AUTOSAR XML (schema 4-2-1)
package /StartApplication/StartApplication_swc/ComponentTypes
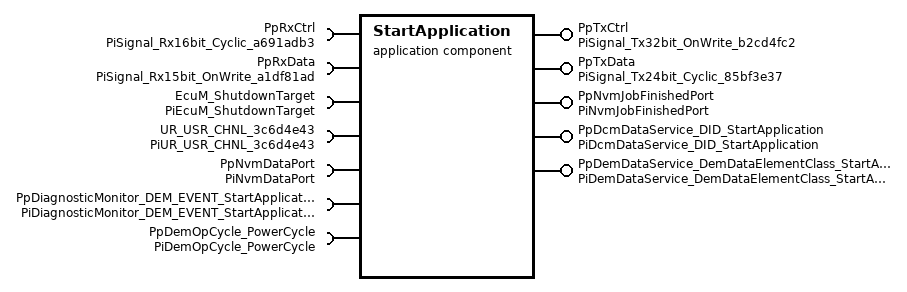
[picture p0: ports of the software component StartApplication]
  application sw component type StartApplication
    provide port PpTxCtrl: nonqueued-sender-com-spec{data-element=DeSignal_Tx32bit_OnWrite_b2cd4fc2, init-value=31}, provided-interface=PiSignal_Tx32bit_OnWrite_b2cd4fc2
    provide port PpTxData: nonqueued-sender-com-spec{data-element=DeSignal_Tx24bit_Cyclic_85bf3e37, init-value=0}, provided-interface=PiSignal_Tx24bit_Cyclic_85bf3e37
    4 x require port:
      PpRxCtrl: nonqueued-receiver-com-spec{data-element=DeSignal_Rx16bit_Cyclic_a691adb3, handle-out-of-range-status=SILENT, init-value=32768}, required-interface=PiSignal_Rx16bit_Cyclic_a691adb3
      PpRxData: nonqueued-receiver-com-spec{data-element=DeSignal_Rx15bit_OnWrite_a1df81ad, handle-out-of-range-status=SILENT, init-value=25}, required-interface=PiSignal_Rx15bit_OnWrite_a1df81ad
      EcuM_ShutdownTarget: required-interface=PiEcuM_ShutdownTarget
      UR_USR_CHNL_3c6d4e43: required-interface=PiUR_USR_CHNL_3c6d4e43
    provide port PpNvmJobFinishedPort: provided-interface=PiNvmJobFinishedPort
    require port PpNvmDataPort: required-interface=PiNvmDataPort
    require port PpDiagnosticMonitor_DEM_EVENT_StartApplication: required-interface=PiDiagnosticMonitor_DEM_EVENT_StartApplication
    require port PpDemOpCycle_PowerCycle: required-interface=PiDemOpCycle_PowerCycle
    provide port PpDcmDataService_DID_StartApplication: provided-interface=PiDcmDataService_DID_StartApplication
    provide port PpDemDataService_DemDataElementClass_StartApplication: provided-interface=PiDemDataService_DemDataElementClass_StartApplication
    behavior StartApplicationInternalBehavior: handle-termination-and-restart=NO-SUPPORT
      ar-typed-per-instance-memorys:
        16 x data:
          TxCtrlSigValue: type=uint32
          TxDataSigValue: type=uint32
          Uptime: type=uint8
          COM_RxSigValue0: type=uint16
          COM_TxSigValue0: type=uint32
          MEM_DataBuffer: type=uint8
          MEM_BlockState: type=EnumMEM_BlockStateType
          DIAG_LastRxData: type=uint8
          NM_ApplState: type=EnumNM_ApplStateType
          NM_ActiveChannelHasFullComRequest: type=uint8
          NM_BusSleepModeTimer: type=uint8
          NM_ActiveComMChannel: type=uint8
          NM_ActiveComMUsers: type=uint32
          XcpPimUpload: sw-calibration-access=READ-WRITE, type=uint16
          XcpPimDownload: sw-calibration-access=READ-WRITE, type=uint16
          ActiveComponent: type=EnumActiveComponentType
      4 x timing event:
        Timer_StartApplication_Cyclic1ms: start-on-event=StartApplication_Cyclic1ms, period=0.001
        Timer_StartApplication_Cyclic10ms: start-on-event=StartApplication_Cyclic10ms, period=0.01
        Timer_StartApplication_Cyclic250ms: start-on-event=StartApplication_Cyclic250ms, period=0.25
        Timer_StartApplication_Cyclic1000ms: start-on-event=StartApplication_Cyclic1000ms, period=1
      init event Timer_StartApplication_Init: start-on-event=StartApplication_Init
      operation invoked event OpEventStartApplication_MEM_JobFinished_JobFinished_PpNvmJobFinishedPort: start-on-event=StartApplication_MEM_JobFinished, operation=PpNvmJobFinishedPort.JobFinished
      data received event DataReceivedEvent_StartApplication_OnDataRec_RxCtrl_PpRxCtrl_DeSignal_Rx16bit_Cyclic_a691adb3: start-on-event=StartApplication_OnDataRec_RxCtrl, data=PpRxCtrl.DeSignal_Rx16bit_Cyclic_a691adb3
      data received event DataReceivedEvent_StartApplication_OnDataRec_RxData_PpRxData_DeSignal_Rx15bit_OnWrite_a1df81ad: start-on-event=StartApplication_OnDataRec_RxData, data=PpRxData.DeSignal_Rx15bit_OnWrite_a1df81ad
      4 x operation invoked event:
        OpEventStartApplication_DIAG_DcmReadData_ReadData_PpDcmDataService_DID_StartApplication: start-on-event=StartApplication_DIAG_DcmReadData, operation=PpDcmDataService_DID_StartApplication.ReadData
        OpEventStartApplication_DIAG_DcmWriteData_WriteData_PpDcmDataService_DID_StartApplication: start-on-event=StartApplication_DIAG_DcmWriteData, operation=PpDcmDataService_DID_StartApplication.WriteData
        OpEventStartApplication_DIAG_ConditionCheckRead_ConditionCheckRead_PpDcmDataService_DID_StartApplication: start-on-event=StartApplication_DIAG_ConditionCheckRead, operation=PpDcmDataService_DID_StartApplication.ConditionCheckRead
        OpEventStartApplication_DIAG_DemReadData_ReadData_PpDemDataService_DemDataElementClass_StartApplication: start-on-event=StartApplication_DIAG_DemReadData, operation=PpDemDataService_DemDataElementClass_StartApplication.ReadData
      explicit-inter-runnable-variables:
        data IrvOccuranceCounterDid: type=uint16, init-value=0
      port-api-options:
        enable-take-address=true, indirect-api=false, port=PpTxCtrl
        enable-take-address=true, indirect-api=false, port=PpTxData
        enable-take-address=true, indirect-api=false, port=PpRxCtrl
        enable-take-address=true, indirect-api=false, port=PpRxData
        enable-take-address=true, indirect-api=false, port=EcuM_ShutdownTarget
        enable-take-address=true, indirect-api=false, port=UR_USR_CHNL_3c6d4e43
        enable-take-address=true, indirect-api=false, port=PpNvmJobFinishedPort
        enable-take-address=true, indirect-api=false, port=PpNvmDataPort
        enable-take-address=true, indirect-api=false, port=PpDiagnosticMonitor_DEM_EVENT_StartApplication
        enable-take-address=true, indirect-api=false, port=PpDemOpCycle_PowerCycle
        enable-take-address=true, indirect-api=false, port=PpDcmDataService_DID_StartApplication
        enable-take-address=true, indirect-api=false, port=PpDemDataService_DemDataElementClass_StartApplication
      12 x runnable:
        StartApplication_Cyclic1ms
        StartApplication_Cyclic10ms
        StartApplication_Cyclic250ms
          data-receive-point-by-arguments:
            access DataReceivePointStartApplication_Cyclic250ms_PpRxData_DeSignal_Rx15bit_OnWrite_a1df81ad: accessed-variable=PpRxData.DeSignal_Rx15bit_OnWrite_a1df81ad
          data-send-points:
            access DataSendPointStartApplication_Cyclic250ms_PpTxCtrl_DeSignal_Tx32bit_OnWrite_b2cd4fc2: accessed-variable=PpTxCtrl.DeSignal_Tx32bit_OnWrite_b2cd4fc2
            access DataSendPointStartApplication_Cyclic250ms_PpTxData_DeSignal_Tx24bit_Cyclic_85bf3e37: accessed-variable=PpTxData.DeSignal_Tx24bit_Cyclic_85bf3e37
          read-local-variables:
            access StartApplication_Cyclic250ms_IrvOccuranceCounterDid_DIRECT_READ: accessed-variable=IrvOccuranceCounterDid
          sync call OpServerCallStartApplication_Cyclic250ms_GetCurrentComMode_UR_USR_CHNL_3c6d4e43: operation=UR_USR_CHNL_3c6d4e43.GetCurrentComMode, timeout=0
          sync call OpServerCallStartApplication_Cyclic250ms_RequestComMode_UR_USR_CHNL_3c6d4e43: operation=UR_USR_CHNL_3c6d4e43.RequestComMode, timeout=0
          sync call OpServerCallStartApplication_Cyclic250ms_ReadBlock_PpNvmDataPort: operation=PpNvmDataPort.ReadBlock, timeout=0
        StartApplication_Cyclic1000ms
        StartApplication_Init: can-be-invoked-concurrently=true
          sync call OpServerCallStartApplication_Init_RequestComMode_UR_USR_CHNL_3c6d4e43: operation=UR_USR_CHNL_3c6d4e43.RequestComMode, timeout=0
        StartApplication_MEM_JobFinished: can-be-invoked-concurrently=true
          data-send-points:
            access DataSendPointStartApplication_MEM_JobFinished_PpTxCtrl_DeSignal_Tx32bit_OnWrite_b2cd4fc2: accessed-variable=PpTxCtrl.DeSignal_Tx32bit_OnWrite_b2cd4fc2
        StartApplication_OnDataRec_RxCtrl
          data-receive-point-by-arguments:
            access DataReceivePointStartApplication_OnDataRec_RxCtrl_PpRxCtrl_DeSignal_Rx16bit_Cyclic_a691adb3: accessed-variable=PpRxCtrl.DeSignal_Rx16bit_Cyclic_a691adb3
          data-send-points:
            access DataSendPointStartApplication_OnDataRec_RxCtrl_PpTxCtrl_DeSignal_Tx32bit_OnWrite_b2cd4fc2: accessed-variable=PpTxCtrl.DeSignal_Tx32bit_OnWrite_b2cd4fc2
          sync call OpServerCallStartApplication_OnDataRec_RxCtrl_SetOperationCycleState_PpDemOpCycle_PowerCycle: operation=PpDemOpCycle_PowerCycle.SetOperationCycleState, timeout=0
        StartApplication_OnDataRec_RxData
          data-receive-point-by-arguments:
            access DataReceivePointStartApplication_OnDataRec_RxData_PpRxData_DeSignal_Rx15bit_OnWrite_a1df81ad: accessed-variable=PpRxData.DeSignal_Rx15bit_OnWrite_a1df81ad
          data-send-points:
            access DataSendPointStartApplication_OnDataRec_RxData_PpTxCtrl_DeSignal_Tx32bit_OnWrite_b2cd4fc2: accessed-variable=PpTxCtrl.DeSignal_Tx32bit_OnWrite_b2cd4fc2
          read-local-variables:
            access StartApplication_OnDataRec_RxData_IrvOccuranceCounterDid_DIRECT_READ: accessed-variable=IrvOccuranceCounterDid
          sync call OpServerCallStartApplication_OnDataRec_RxData_SelectShutdownTarget_EcuM_ShutdownTarget: operation=EcuM_ShutdownTarget.SelectShutdownTarget, timeout=0
          sync call OpServerCallStartApplication_OnDataRec_RxData_WriteBlock_PpNvmDataPort: operation=PpNvmDataPort.WriteBlock, timeout=0
          sync call OpServerCallStartApplication_OnDataRec_RxData_SetEventStatus_PpDiagnosticMonitor_DEM_EVENT_StartApplication: operation=PpDiagnosticMonitor_DEM_EVENT_StartApplication.SetEventStatus, timeout=0
          written-local-variables:
            access StartApplication_OnDataRec_RxData_IrvOccuranceCounterDid_DIRECT_WRITE: accessed-variable=IrvOccuranceCounterDid
        StartApplication_DIAG_DcmReadData: can-be-invoked-concurrently=true
          read-local-variables:
            access StartApplication_DIAG_DcmReadData_IrvOccuranceCounterDid_DIRECT_READ: accessed-variable=IrvOccuranceCounterDid
        StartApplication_DIAG_DcmWriteData: can-be-invoked-concurrently=true
          written-local-variables:
            access StartApplication_DIAG_DcmWriteData_IrvOccuranceCounterDid_DIRECT_WRITE: accessed-variable=IrvOccuranceCounterDid
        StartApplication_DIAG_ConditionCheckRead: can-be-invoked-concurrently=true
        StartApplication_DIAG_DemReadData: can-be-invoked-concurrently=true
          read-local-variables:
            access StartApplication_DIAG_DemReadData_IrvOccuranceCounterDid_DIRECT_READ: accessed-variable=IrvOccuranceCounterDid
  swc implementation StartApplicationImplementation: programming-language=C, behavior=StartApplicationInternalBehavior
package /StartApplication/StartApplication_swc/DataTypes
  14 x impl type:
    EnumMEM_BlockStateType: compu {0=MEM_STATE_UNKNOWN, 1=MEM_STATE_WRITE_PENDING, 2=MEM_STATE_WRITE_FINISHED, 3=MEM_STATE_READ_PENDING, 4=MEM_STATE_READ_FINISHED, 5=MEM_STATE_WRITE_FAILED, 6=MEM_STATE_READ_FAILED}, implementation-data-type=uint8
    EnumNM_ApplStateType: compu {0=NM_APPL_STATE_FULL_COMM_EXTERN, 1=NM_APPL_STATE_FULL_COMM_INTERN, 2=NM_APPL_STATE_NO_COMM_EXTERN}, implementation-data-type=uint8
    EcuM_StateType: compu {15=ECUM_SUBSTATE_MASK, 16=ECUM_STATE_STARTUP, 17=ECUM_STATE_STARTUP_ONE, 18=ECUM_STATE_STARTUP_TWO, 32=ECUM_STATE_WAKEUP, 33=ECUM_STATE_WAKEUP_ONE, 34=ECUM_STATE_WAKEUP_VALIDATION, 35=ECUM_STATE_WAKEUP_REACTION, 36=ECUM_STATE_WAKEUP_TWO, 37=ECUM_STATE_WAKEUP_WAKESLEEP, 38=ECUM_STATE_WAKEUP_TTII, 48=ECUM_STATE_RUN, 50=ECUM_STATE_APP_RUN, 51=ECUM_STATE_APP_POST_RUN, 64=ECUM_STATE_SHUTDOWN, 68=ECUM_STATE_PREP_SHUTDOWN, 73=ECUM_STATE_GO_SLEEP, 77=ECUM_STATE_GO_OFF_ONE, 78=ECUM_STATE_GO_OFF_TWO, 80=ECUM_STATE_SLEEP, 128=ECUM_STATE_OFF, 144=ECUM_STATE_RESET}, implementation-data-type=uint8
    EcuM_SleepModeType: implementation-data-type=uint8
    EcuM_ShutdownCauseType: compu {0=ECUM_CAUSE_UNKNOWN, 1=ECUM_CAUSE_ECU_STATE, 2=ECUM_CAUSE_WDGM, 3=ECUM_CAUSE_DCM}, implementation-data-type=uint8
    ComM_ModeType: compu {0=COMM_NO_COMMUNICATION, 1=COMM_SILENT_COMMUNICATION, 2=COMM_FULL_COMMUNICATION}, implementation-data-type=uint8
    NvM_ServiceIdType: compu {6=NVM_READ_BLOCK, 7=NVM_WRITE_BLOCK, 8=NVM_RESTORE_BLOCK_DEFAULTS, 9=NVM_ERASE_BLOCK, 11=NVM_INVALIDATE_NV_BLOCK, 12=NVM_READ_ALL}, implementation-data-type=uint8
    NvM_RequestResultType: compu {0=NVM_REQ_OK, 1=NVM_REQ_NOT_OK, 2=NVM_REQ_PENDING, 3=NVM_REQ_INTEGRITY_FAILED, 4=NVM_REQ_BLOCK_SKIPPED, 5=NVM_REQ_NV_INVALIDATED, 6=NVM_REQ_CANCELED, 7=NVM_REQ_REDUNDANCY_FAILED, 8=NVM_REQ_RESTORED_FROM_ROM}, implementation-data-type=uint8
    Dem_EventStatusType: compu {0=DEM_EVENT_STATUS_PASSED, 1=DEM_EVENT_STATUS_FAILED, 2=DEM_EVENT_STATUS_PREPASSED, 3=DEM_EVENT_STATUS_PREFAILED, 4=DEM_EVENT_STATUS_FDC_THRESHOLD_REACHED}, implementation-data-type=uint8
    Dem_OperationCycleStateType: compu {0=DEM_CYCLE_STATE_START, 1=DEM_CYCLE_STATE_END}, implementation-data-type=uint8
    Dcm_Data2ByteType: category=ARRAY, sw-calibration-access=READ-ONLY
      element Dcm_Data2ByteTypeElement: array-size=2, array-size-semantics=FIXED-SIZE, implementation-data-type=uint8
    Dcm_NegativeResponseCodeType: compu {0=DCM_E_POSITIVERESPONSE, 16=DCM_E_GENERALREJECT, 17=DCM_E_SERVICENOTSUPPORTED, 18=DCM_E_SUBFUNCTIONNOTSUPPORTED, 19=DCM_E_INCORRECTMESSAGELENGTHORINVALIDFORMAT, 20=DCM_E_RESPONSETOOLONG, 33=DCM_E_BUSYREPEATREQUEST, 34=DCM_E_CONDITIONSNOTCORRECT, 36=DCM_E_REQUESTSEQUENCEERROR, 37=DCM_E_NORESPONSEFROMSUBNETCOMPONENT, 38=DCM_E_FAILUREPREVENTSEXECUTIONOFREQUESTEDACTION, 49=DCM_E_REQUESTOUTOFRANGE, 51=DCM_E_SECURITYACCESSDENIED, 53=DCM_E_INVALIDKEY, 54=DCM_E_EXCEEDNUMBEROFATTEMPTS, 55=DCM_E_REQUIREDTIMEDELAYNOTEXPIRED, 112=DCM_E_UPLOADDOWNLOADNOTACCEPTED, 113=DCM_E_TRANSFERDATASUSPENDED, 114=DCM_E_GENERALPROGRAMMINGFAILURE, 115=DCM_E_WRONGBLOCKSEQUENCECOUNTER, 120=DCM_E_REQUESTCORRECTLYRECEIVEDRESPONSEPENDING, 126=DCM_E_SUBFUNCTIONNOTSUPPORTEDINACTIVESESSION, 127=DCM_E_SERVICENOTSUPPORTEDINACTIVESESSION, 129=DCM_E_RPMTOOHIGH, 130=DCM_E_RPMTOOLOW, 131=DCM_E_ENGINEISRUNNING, 132=DCM_E_ENGINEISNOTRUNNING, 133=DCM_E_ENGINERUNTIMETOOLOW, 134=DCM_E_TEMPERATURETOOHIGH, 135=DCM_E_TEMPERATURETOOLOW, 136=DCM_E_VEHICLESPEEDTOOHIGH, 137=DCM_E_VEHICLESPEEDTOOLOW, 138=DCM_E_THROTTLE_PEDALTOOHIGH, 139=DCM_E_THROTTLE_PEDALTOOLOW, 140=DCM_E_TRANSMISSIONRANGENOTINNEUTRAL, 141=DCM_E_TRANSMISSIONRANGENOTINGEAR, 143=DCM_E_BRAKESWITCH_NOTCLOSED, 144=DCM_E_SHIFTERLEVERNOTINPARK, 145=DCM_E_TORQUECONVERTERCLUTCHLOCKED, 146=DCM_E_VOLTAGETOOHIGH, 147=DCM_E_VOLTAGETOOLOW}, implementation-data-type=uint8
    DataArray_Type_2: category=ARRAY, sw-calibration-access=READ-ONLY
      element DataArray_Type_2Element: array-size=2, array-size-semantics=FIXED-SIZE, implementation-data-type=uint8
    EnumActiveComponentType: compu {0=STARTAPPLICATION_ACTIVE_COMPONENT_COM_RXTX, 1=STARTAPPLICATION_ACTIVE_COMPONENT_MEM, 2=STARTAPPLICATION_ACTIVE_COMPONENT_DIAG, 3=STARTAPPLICATION_ACTIVE_COMPONENT_COM_TXONLY, 5=STARTAPPLICATION_ACTIVE_COMPONENT_XCP, 10=STARTAPPLICATION_ACTIVE_COMPONENT_NM, 255=STARTAPPLICATION_ACTIVE_COMPONENT_INVALID}, implementation-data-type=uint8
package /StartApplication/StartApplication_swc/Interfaces
  4 x sender receiver interface:
    PiSignal_Tx32bit_OnWrite_b2cd4fc2
      data DeSignal_Tx32bit_OnWrite_b2cd4fc2: type=uint32
    PiSignal_Tx24bit_Cyclic_85bf3e37
      data DeSignal_Tx24bit_Cyclic_85bf3e37: type=uint32
    PiSignal_Rx16bit_Cyclic_a691adb3
      data DeSignal_Rx16bit_Cyclic_a691adb3: type=uint16
    PiSignal_Rx15bit_OnWrite_a1df81ad
      data DeSignal_Rx15bit_OnWrite_a1df81ad: type=uint16
  8 x client server interface, all with is-service=true, service-kind=VENDOR-SPECIFIC:
    PiEcuM_ShutdownTarget
      5 x operation, all with possible-error=PiEcuM_ShutdownTarget/E_NOT_OK:
        SelectShutdownTarget
          arg targetState: type=EcuM_StateType, direction=IN
          arg resetSleepMode: type=EcuM_SleepModeType, direction=IN
        GetShutdownTarget
          arg target: type=EcuM_StateType, direction=OUT
          arg resetSleepMode: type=EcuM_SleepModeType, direction=OUT
        GetLastShutdownTarget
          arg target: type=EcuM_StateType, direction=OUT
          arg resetSleepMode: type=EcuM_SleepModeType, direction=OUT
        SelectShutdownCause
          arg shutdownCause: type=EcuM_ShutdownCauseType, direction=IN
        GetShutdownCause
          arg shutdownCause: type=EcuM_ShutdownCauseType, direction=OUT
      error E_NOT_OK: error-code=1
    PiUR_USR_CHNL_3c6d4e43
      4 x operation:
        GetCurrentComMode: possible-error=PiUR_USR_CHNL_3c6d4e43/E_NOT_OK
          arg ComMode: type=ComM_ModeType, direction=OUT
        GetMaxComMode: possible-error=PiUR_USR_CHNL_3c6d4e43/E_NOT_OK
          arg ComMode: type=ComM_ModeType, direction=OUT
        GetRequestedComMode: possible-error=PiUR_USR_CHNL_3c6d4e43/E_NOT_OK
          arg ComMode: type=ComM_ModeType, direction=OUT
        RequestComMode: possible-error=[PiUR_USR_CHNL_3c6d4e43/E_NOT_OK, E_MODE_LIMITATION]
          arg ComMode: type=ComM_ModeType, direction=IN
      error E_NOT_OK: error-code=1
      error E_MODE_LIMITATION: error-code=2
    PiNvmDataPort
      operation WriteBlock: possible-error=PiNvmDataPort/E_NOT_OK
        arg SrcPtr: type=dtRef_const_VOID, direction=IN
      operation ReadBlock: possible-error=PiNvmDataPort/E_NOT_OK
        arg DstPtr: type=dtRef_VOID, direction=IN
      error E_NOT_OK: error-code=1
    PiNvmJobFinishedPort
      operation JobFinished
        arg ServiceId: type=NvM_ServiceIdType, direction=IN
        arg JobResult: type=NvM_RequestResultType, direction=IN
    PiDiagnosticMonitor_DEM_EVENT_StartApplication
      operation SetEventStatus: possible-error=PiDiagnosticMonitor_DEM_EVENT_StartApplication/E_NOT_OK
        arg EventStatus: type=Dem_EventStatusType, direction=IN
      operation ResetEventStatus: possible-error=PiDiagnosticMonitor_DEM_EVENT_StartApplication/E_NOT_OK
      error E_NOT_OK: error-code=1
    PiDemOpCycle_PowerCycle
      operation SetOperationCycleState: possible-error=PiDemOpCycle_PowerCycle/E_NOT_OK
        arg CycleState: type=Dem_OperationCycleStateType, direction=IN
      error E_NOT_OK: error-code=1
    PiDcmDataService_DID_StartApplication
      operation WriteData
        arg Data: type=Dcm_Data2ByteType, direction=IN
        arg ErrorCode: type=Dcm_NegativeResponseCodeType, direction=OUT
      operation ReadData
        arg Data: type=Dcm_Data2ByteType, direction=OUT
      operation ConditionCheckRead
        arg ErrorCode: type=Dcm_NegativeResponseCodeType, direction=OUT
    PiDemDataService_DemDataElementClass_StartApplication
      operation ReadData
        arg Data: type=DataArray_Type_2, direction=OUT
